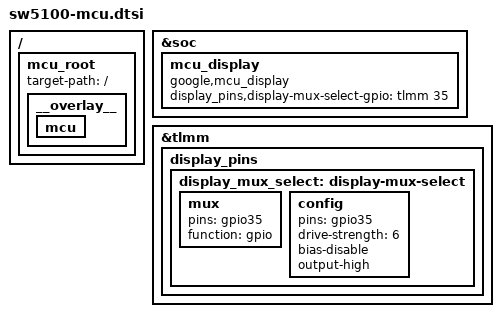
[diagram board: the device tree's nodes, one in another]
// SPDX-License-Identifier: GPL-2.0

#include <dt-bindings/gpio/gpio.h>

// MCU root node and common definitions, available at /proc/device-tree/mcu.
/ {
	mcu_root {
		target-path = "/";
		__overlay__ {
			mcu: mcu {};
		};
	};
};

&soc {
	mcu_display: mcu_display {
		compatible = "google,mcu_display";
		display_pins,display-mux-select-gpio = <&tlmm 35 IRQ_TYPE_NONE>;
	};
};

&tlmm {
	display_pins {
		display_mux_select: display-mux-select {
			mux {
				pins = "gpio35";
				function = "gpio";
			};
			config {
				pins = "gpio35";
				drive-strength = <6>;
				bias-disable;
				output-high;
			};
		};
	};
};
